# j7aen_main_ctrl_mmr0_CFG0 register map
Vendor: Texas Instruments
Peripheral module from a debugger description file (folder J722S).
Registers are 32-bit, read-write, reset 0x0 unless marked. A register's access mark holds for its fields unless they carry their own. Offsets are as the file gives them; lines under a group give offsets from that group; [hi:lo] are bit positions; {n}, {i} and the like mark numbered series; 'fields as' and 'values as' point back to an identical list; <NAME> marks a mode.

## j7aen_main_ctrl_mmr0_CFG0 (part 1 of 2)
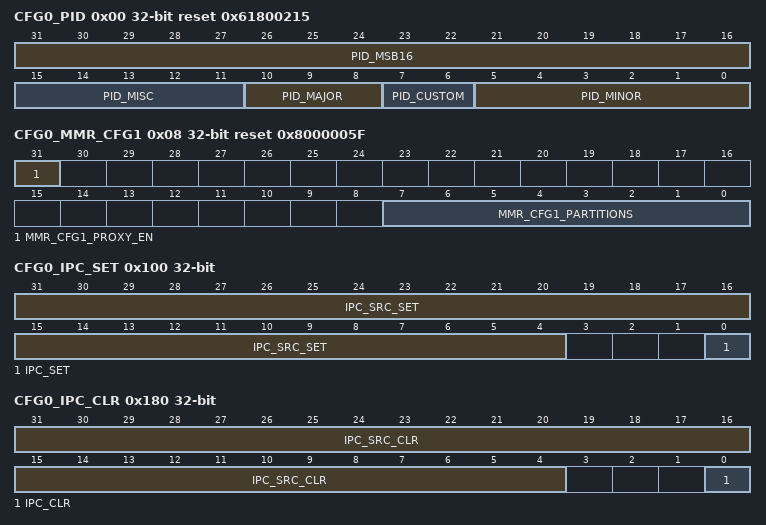
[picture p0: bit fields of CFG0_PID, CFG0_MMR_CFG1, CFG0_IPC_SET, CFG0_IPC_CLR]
0x00 CFG0_PID ro reset 0x61800215
  [31:16] PID_MSB16, [15:11] PID_MISC, [10:8] PID_MAJOR, [7:6] PID_CUSTOM, [5:0] PID_MINOR
0x08 CFG0_MMR_CFG1 ro reset 0x8000005F
  [31] MMR_CFG1_PROXY_EN — Proxy addressing activated
  [7:0] MMR_CFG1_PARTITIONS — Indicates present partitions
0x100 CFG0_IPC_SET access not given
  [31:4] IPC_SRC_SET — Read returns current value Write: 0 - No effect 1 - Sets both corresponding IPC_CLR and the IPC_SET bits (access R/W1TS)
  [0] IPC_SET — Read returns 0 Write: 0 - No effect 1 - Sets both corresponding IPC_CLR and the IPC_SET bits (access R/W1TS)
0x180 CFG0_IPC_CLR access not given
  [31:4] IPC_SRC_CLR — Read returns current value Write: 0 - No effect 1 - Clears both corresponding IPC_CLR and the IPC_SET bits (access R/W1TC)
  [0] IPC_CLR — Read returns current value Write: 0 - No effect 1 - Clears both corresponding IPC_CLR and the IPC_SET bits (access R/W1TC)
{0x1008+0x4000*i} CFG0_LOCK{i}_KICK0 (i=0..4)
  [31:0] LOCK{i}_KICK0 — - KICK0 component
{0x100C+0x4000*i} CFG0_LOCK{i}_KICK1 (i=0..4)
  [31:0] LOCK{i}_KICK1 — - KICK1 component
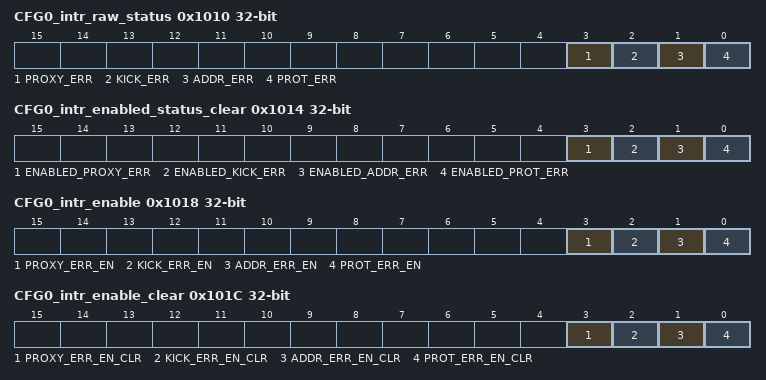
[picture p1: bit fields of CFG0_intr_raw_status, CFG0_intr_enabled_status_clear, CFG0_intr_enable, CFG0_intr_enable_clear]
0x1010 CFG0_intr_raw_status access not given
  [3] PROXY_ERR — Proxy0 access violation error. Raw status is read. Write a 1 to set the status. Writing a 0 has no effect. (access R/W1TS)
  [2] KICK_ERR — Kick access violation error. Raw status is read. Write a 1 to set the status. Writing a 0 has no effect. (access R/W1TS)
  [1] ADDR_ERR — Addressing violation error. Raw status is read. Write a 1 to set the status. Writing a 0 has no effect. (access R/W1TS)
  [0] PROT_ERR — Protection violation error. Raw status is read. Write a 1 to set the status. Writing a 0 has no effect. (access R/W1TS)
0x1014 CFG0_intr_enabled_status_clear access not given
  [3] ENABLED_PROXY_ERR — Proxy0 access violation error. Enabled status is read. Write a 1 to clear the status. Writing a 0 has no effect. (access R/W1TC)
  [2] ENABLED_KICK_ERR — Kick access violation error. Enabled status is read. Write a 1 to clear the status. Writing a 0 has no effect. (access R/W1TC)
  [1] ENABLED_ADDR_ERR — Addressing violation error. Enabled status is read. Write a 1 to clear the status. Writing a 0 has no effect. (access R/W1TC)
  [0] ENABLED_PROT_ERR — Protection violation error. Enabled status is read. Write a 1 to clear the status. Writing a 0 has no effect. (access R/W1TC)
0x1018 CFG0_intr_enable access not given
  [3] PROXY_ERR_EN — Proxy0 access violation error enable. Write a 1 to set the enable. Writing a 0 has no effect. (access R/W1TS)
  [2] KICK_ERR_EN — Kick access violation error enable. Write a 1 to set the enable. Writing a 0 has no effect. (access R/W1TS)
  [1] ADDR_ERR_EN — Addressing violation error enable. Write a 1 to set the enable. Writing a 0 has no effect. (access R/W1TS)
  [0] PROT_ERR_EN — Protection violation error enable. Write a 1 to set the enable. Writing a 0 has no effect. (access R/W1TS)
0x101C CFG0_intr_enable_clear access not given
  [3] PROXY_ERR_EN_CLR — Proxy0 access violation error enable clear. Write a 1 to clear the enable. Writing a 0 has no effect. (access R/W1TC)
  [2] KICK_ERR_EN_CLR — Kick access violation error enable clear. Write a 1 to clear the enable. Writing a 0 has no effect. (access R/W1TC)
  [1] ADDR_ERR_EN_CLR — Addressing violation error enable clear. Write a 1 to clear the enable. Writing a 0 has no effect. (access R/W1TC)
  [0] PROT_ERR_EN_CLR — Protection violation error enable clear. Write a 1 to clear the enable. Writing a 0 has no effect. (access R/W1TC)
0x1020 CFG0_eoi
  [7:0] EOI_VECTOR — EOI vector value. Write this with interrupt distribution value in the chip.
0x1024 CFG0_fault_address ro
  [31:0] FAULT_ADDR — Fault Address.
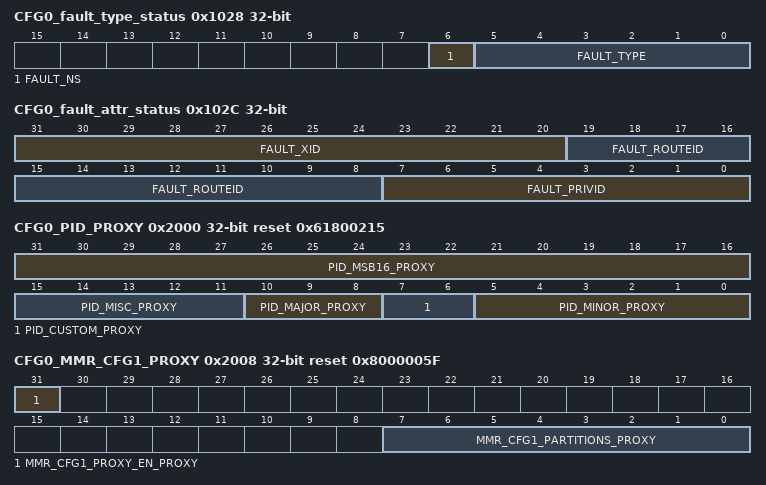
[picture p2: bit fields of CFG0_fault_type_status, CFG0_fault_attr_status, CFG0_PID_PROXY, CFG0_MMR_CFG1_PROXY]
0x1028 CFG0_fault_type_status ro
  [6] FAULT_NS — Non-secure access.
  [5:0] FAULT_TYPE — Fault Type 10_0000 = Supervisor read fault - priv = 1 dir = 1 dtype != 1 01_0000 = Supervisor write fault - priv = 1 dir = 0 00_1000 = Supervisor execute fault - priv = 1 dir = 1 dtype = 1 00_0100 = User read fault - priv = 0 dir = 1 dtype = 1 00_0010 = User write fault - priv = 0 dir = 0 00_0001 = User execute fault - priv = 0 dir = 1 dtype = 1 00_0000 = No fault
0x102C CFG0_fault_attr_status ro
  [31:20] FAULT_XID — XID.
  [19:8] FAULT_ROUTEID — Route ID.
  [7:0] FAULT_PRIVID — Privilege ID.
0x1030 CFG0_fault_clear wo
  [0] FAULT_CLR — Fault clear. Writing a 1 clears the current fault. Writing a 0 has no effect.
{0x1100+4i} CFG0_CLAIMREG_P0_R{i}_READONLY ro (i=0..6)
  [31:0] CLAIMREG_P0_R{i}_READONLY — Claim bits for Partition 0
0x2000 CFG0_PID_PROXY ro reset 0x61800215
  [31:16] PID_MSB16_PROXY, [15:11] PID_MISC_PROXY, [10:8] PID_MAJOR_PROXY, [7:6] PID_CUSTOM_PROXY, [5:0] PID_MINOR_PROXY
0x2008 CFG0_MMR_CFG1_PROXY ro reset 0x8000005F
  [31] MMR_CFG1_PROXY_EN_PROXY — Proxy addressing activated
  [7:0] MMR_CFG1_PARTITIONS_PROXY — Indicates present partitions
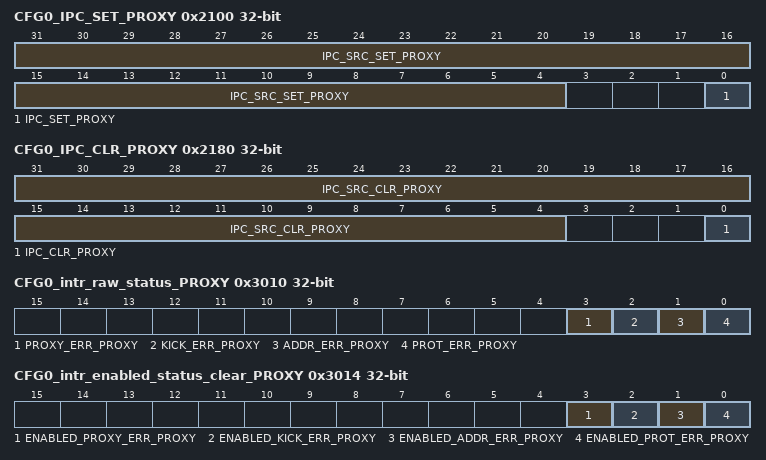
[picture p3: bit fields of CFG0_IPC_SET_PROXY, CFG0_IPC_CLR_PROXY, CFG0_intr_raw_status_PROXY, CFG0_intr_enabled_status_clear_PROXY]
0x2100 CFG0_IPC_SET_PROXY access not given
  [31:4] IPC_SRC_SET_PROXY — Read returns current value Write: 0 - No effect 1 - Sets both corresponding IPC_CLR and the IPC_SET bits (access R/W1TS)
  [0] IPC_SET_PROXY — Read returns 0 Write: 0 - No effect 1 - Sets both corresponding IPC_CLR and the IPC_SET bits (access R/W1TS)
0x2180 CFG0_IPC_CLR_PROXY access not given
  [31:4] IPC_SRC_CLR_PROXY — Read returns current value Write: 0 - No effect 1 - Clears both corresponding IPC_CLR and the IPC_SET bits (access R/W1TC)
  [0] IPC_CLR_PROXY — Read returns current value Write: 0 - No effect 1 - Clears both corresponding IPC_CLR and the IPC_SET bits (access R/W1TC)
{0x3008+0x4000*i} CFG0_LOCK{i}_KICK0_PROXY (i=0..4)
  [31:0] LOCK{i}_KICK0_PROXY — - KICK0 component
{0x300C+0x4000*i} CFG0_LOCK{i}_KICK1_PROXY (i=0..4)
  [31:0] LOCK{i}_KICK1_PROXY — - KICK1 component
0x3010 CFG0_intr_raw_status_PROXY access not given
  [3] PROXY_ERR_PROXY — Proxy0 access violation error. Raw status is read. Write a 1 to set the status. Writing a 0 has no effect. (access R/W1TS)
  [2] KICK_ERR_PROXY — Kick access violation error. Raw status is read. Write a 1 to set the status. Writing a 0 has no effect. (access R/W1TS)
  [1] ADDR_ERR_PROXY — Addressing violation error. Raw status is read. Write a 1 to set the status. Writing a 0 has no effect. (access R/W1TS)
  [0] PROT_ERR_PROXY — Protection violation error. Raw status is read. Write a 1 to set the status. Writing a 0 has no effect. (access R/W1TS)
0x3014 CFG0_intr_enabled_status_clear_PROXY access not given
  [3] ENABLED_PROXY_ERR_PROXY — Proxy0 access violation error. Enabled status is read. Write a 1 to clear the status. Writing a 0 has no effect. (access R/W1TC)
  [2] ENABLED_KICK_ERR_PROXY — Kick access violation error. Enabled status is read. Write a 1 to clear the status. Writing a 0 has no effect. (access R/W1TC)
  [1] ENABLED_ADDR_ERR_PROXY — Addressing violation error. Enabled status is read. Write a 1 to clear the status. Writing a 0 has no effect. (access R/W1TC)
  [0] ENABLED_PROT_ERR_PROXY — Protection violation error. Enabled status is read. Write a 1 to clear the status. Writing a 0 has no effect. (access R/W1TC)
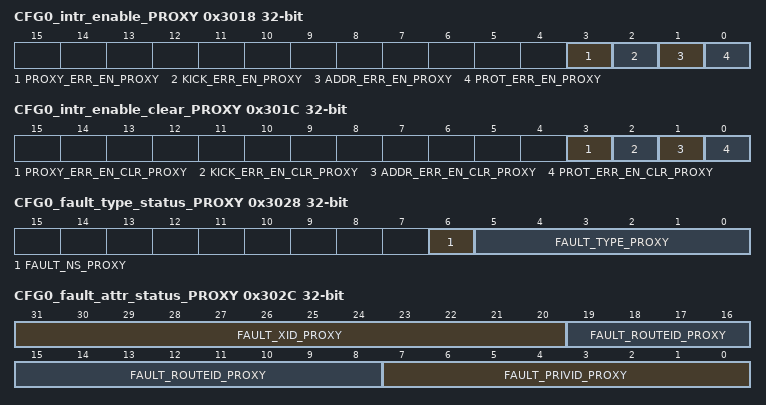
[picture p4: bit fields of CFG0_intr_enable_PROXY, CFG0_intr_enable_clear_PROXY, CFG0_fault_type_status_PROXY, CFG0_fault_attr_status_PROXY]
0x3018 CFG0_intr_enable_PROXY access not given
  [3] PROXY_ERR_EN_PROXY — Proxy0 access violation error enable. Write a 1 to set the enable. Writing a 0 has no effect. (access R/W1TS)
  [2] KICK_ERR_EN_PROXY — Kick access violation error enable. Write a 1 to set the enable. Writing a 0 has no effect. (access R/W1TS)
  [1] ADDR_ERR_EN_PROXY — Addressing violation error enable. Write a 1 to set the enable. Writing a 0 has no effect. (access R/W1TS)
  [0] PROT_ERR_EN_PROXY — Protection violation error enable. Write a 1 to set the enable. Writing a 0 has no effect. (access R/W1TS)
0x301C CFG0_intr_enable_clear_PROXY access not given
  [3] PROXY_ERR_EN_CLR_PROXY — Proxy0 access violation error enable clear. Write a 1 to clear the enable. Writing a 0 has no effect. (access R/W1TC)
  [2] KICK_ERR_EN_CLR_PROXY — Kick access violation error enable clear. Write a 1 to clear the enable. Writing a 0 has no effect. (access R/W1TC)
  [1] ADDR_ERR_EN_CLR_PROXY — Addressing violation error enable clear. Write a 1 to clear the enable. Writing a 0 has no effect. (access R/W1TC)
  [0] PROT_ERR_EN_CLR_PROXY — Protection violation error enable clear. Write a 1 to clear the enable. Writing a 0 has no effect. (access R/W1TC)
0x3020 CFG0_eoi_PROXY
  [7:0] EOI_VECTOR_PROXY — EOI vector value. Write this with interrupt distribution value in the chip.
0x3024 CFG0_fault_address_PROXY ro
  [31:0] FAULT_ADDR_PROXY — Fault Address.
0x3028 CFG0_fault_type_status_PROXY ro
  [6] FAULT_NS_PROXY — Non-secure access.
  [5:0] FAULT_TYPE_PROXY — Fault Type 10_0000 = Supervisor read fault - priv = 1 dir = 1 dtype != 1 01_0000 = Supervisor write fault - priv = 1 dir = 0 00_1000 = Supervisor execute fault - priv = 1 dir = 1 dtype = 1 00_0100 = User read fault - priv = 0 dir = 1 dtype = 1 00_0010 = User write fault - priv = 0 dir = 0 00_0001 = User execute fault - priv = 0 dir = 1 dtype = 1 00_0000 = No fault
0x302C CFG0_fault_attr_status_PROXY ro
  [31:20] FAULT_XID_PROXY — XID.
  [19:8] FAULT_ROUTEID_PROXY — Route ID.
  [7:0] FAULT_PRIVID_PROXY — Privilege ID.
0x3030 CFG0_fault_clear_PROXY wo
  [0] FAULT_CLR_PROXY — Fault clear. Writing a 1 clears the current fault. Writing a 0 has no effect.
{0x3100+4i} CFG0_CLAIMREG_P0_R{i} (i=0..6)
  [31:0] CLAIMREG_P0_R{i} — Claim bits for Partition 0
0x4044 CFG0_ENET1_CTRL reset 0x2
  [2:0] ENET1_CTRL_PORT_MODE_SEL — Selects Ethernet switch Port1 interface Field values (others are reserved): 3'b000 - GMII/MII (not supported) 3'b001 - RMII 3'b010 - RGMII 3'b011 - SGMII 3'b100 - QSGMII (not supported) 3'b101 - XFI (not supported) 3'b110 - QSGMII_SUB (not supported) 3'b111 - Reserved
0x4048 CFG0_ENET2_CTRL reset 0x2
  [2:0] ENET2_CTRL_PORT_MODE_SEL — Selects Ethernet switch Port2 interface Field values (others are reserved): 3'b000 - GMII/MII (not supported) 3'b001 - RMII 3'b010 - RGMII 3'b011 - SGMII 3'b100 - QSGMII (not supported) 3'b101 - XFI (not supported) 3'b110 - QSGMII_SUB (not supported) 3'b111 - Reserved
0x4080 CFG0_SERDES0_LN0_CTRL
  [1:0] SERDES0_LN0_CTRL_LANE_FUNC_SEL — Selects the SERDES0 lane0 function Field values (others are reserved): 2'b00 - USBSS0 2'b01 - CPSW0_SGMII2
0x4090 CFG0_SERDES1_LN0_CTRL
  [1:0] SERDES1_LN0_CTRL_LANE_FUNC_SEL — Selects the SERDES1 lane0 function Field values (others are reserved): undefined - undefined undefined - undefined undefined - undefined undefined - undefined 2'b00 - PCIE0 2'b01 - CPSW0_SGMII1
0x40E0 CFG0_SERDES0_CTRL
  [8] SERDES0_CTRL_RET_EN — Retention activate Field values (others are reserved): 1'b0 - DEACTIVATE 1'b1 - ACTIVATE
0x40E4 CFG0_SERDES1_CTRL
  [8] SERDES1_CTRL_RET_EN — Retention activate Field values (others are reserved): 1'b0 - DEACTIVATE 1'b1 - ACTIVATE
0x4128 CFG0_DPI0_OUT_SEL reset 0x1
  [1:0] DPI0_OUT_SEL_OUTSEL — Selects Source of DPI0 output Field values (others are reserved): undefined - undefined 2'b01 - DSS0_DISPC0_DPI1 2'b10 - DSS1_DISPC0_DPI0 2'b11 - DSS1_DISPC0_DPI1
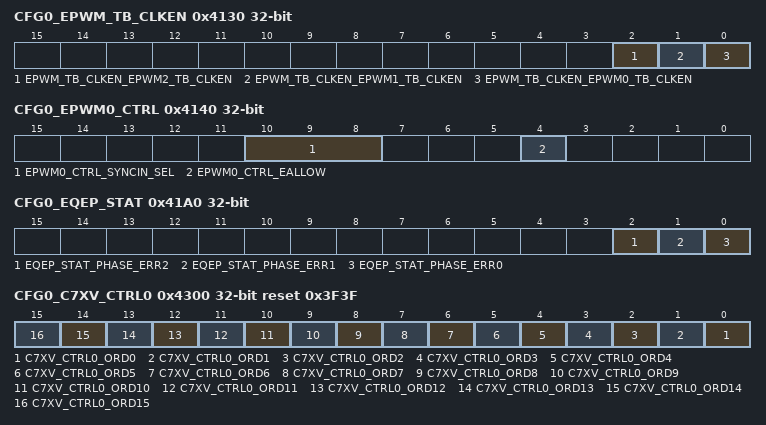
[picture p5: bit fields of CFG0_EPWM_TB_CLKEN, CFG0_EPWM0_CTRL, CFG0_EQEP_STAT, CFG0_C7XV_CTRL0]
0x4130 CFG0_EPWM_TB_CLKEN
  [2] EPWM_TB_CLKEN_EPWM2_TB_CLKEN — Activates Timebase Clock of EPWM2 When Set Field values (others are reserved): 1'b0 - DEACTIVATE 1'b1 - ACTIVATE
  [1] EPWM_TB_CLKEN_EPWM1_TB_CLKEN — Activates Timebase Clock of EPWM1 When Set Field values (others are reserved): 1'b0 - DEACTIVATE 1'b1 - ACTIVATE
  [0] EPWM_TB_CLKEN_EPWM0_TB_CLKEN — Activates Timebase Clock of EPWM0 When Set Field values (others are reserved): 1'b0 - DEACTIVATE 1'b1 - ACTIVATE
0x4140 CFG0_EPWM0_CTRL
  [10:8] EPWM0_CTRL_SYNCIN_SEL — Selects the source of the EPWM0 synchronization input Field values (others are reserved): 3'b000 - EPWM0_SYNCIN (Pin) undefined - undefined 3'b010 - Time Sync Router 19 3'b011 - CPSW CMP Event 3'b100 - PCI CMP Event
  [4] EPWM0_CTRL_EALLOW — Activate write access to EPWM tripzone registers Field values (others are reserved): 1'b0 - DEACTIVATE 1'b1 - ACTIVATE
0x4144 CFG0_EPWM1_CTRL
  [4] EPWM1_CTRL_EALLOW — Activate write access to EPWM tripzone registers Field values (others are reserved): 1'b0 - DEACTIVATE 1'b1 - ACTIVATE
0x4148 CFG0_EPWM2_CTRL
  [4] EPWM2_CTRL_EALLOW — Activate write access to EPWM tripzone registers Field values (others are reserved): 1'b0 - DEACTIVATE 1'b1 - ACTIVATE
{0x4180+4i} CFG0_EQEP{i}_CTRL (i=0..2)
  [4:0] EQEP{i}_CTRL_SOCA_SEL — Selects the source of SOCA input for EQEP{i} Field values (others are reserved): undefined - undefined undefined - undefined 5'b00010 - EPWM SOCA_OUT 5'b00011 - EPWM SOCB_OUT 5'b00100 - MCU_TIMER0 PWM 5'b00101 - MCU_TIMER1 PWM 5'b00110 - MCU_TIMER2 PWM 5'b00111 - MCU_TIMER3 PWM 5'b01000 - TIMER0 PWM 5'b01001 - TIMER1 PWM 5'b01010 - TIMER2 PWM 5'b01011 - TIMER3 PWM 5'b01100 - TIMER4 PWM 5'b01101 - TIMER5 PWM 5'b01110 - TIMER6 PWM 5'b01111 - TIMER7 PWM 5'b10000 - WKUP TIMER0 PWM undefined - undefined 5'b10001 - WKUP TIMER1 PWM
0x41A0 CFG0_EQEP_STAT ro
  [2] EQEP_STAT_PHASE_ERR2 — EQEP2 Phase error status Field values (others are reserved): 1'b0 - NO_ERROR 1'b1 - PHASE_ERROR
  [1] EQEP_STAT_PHASE_ERR1 — EQEP1 Phase error status Field values (others are reserved): 1'b0 - NO_ERROR 1'b1 - PHASE_ERROR
  [0] EQEP_STAT_PHASE_ERR0 — EQEP0 Phase error status Field values (others are reserved): 1'b0 - NO_ERROR 1'b1 - PHASE_ERROR
0x4204 CFG0_TIMER1_CTRL
  [8] TIMER1_CTRL_CASCADE_EN — Activates cascading of TIMER1 to TIMER0 Field values (others are reserved): 1'b0 - CASCADE_DEACTIVATED 1'b1 - CASCADE_ACTIVATED
0x420C CFG0_TIMER3_CTRL
  [8] TIMER3_CTRL_CASCADE_EN — Activates cascading of TIMER3 to TIMER2 Field values (others are reserved): 1'b0 - CASCADE_DEACTIVATED 1'b1 - CASCADE_ACTIVATED
0x4214 CFG0_TIMER5_CTRL
  [8] TIMER5_CTRL_CASCADE_EN — Activates cascading of TIMER5 to TIMER4 Field values (others are reserved): 1'b0 - CASCADE_DEACTIVATED 1'b1 - CASCADE_ACTIVATED
0x421C CFG0_TIMER7_CTRL
  [8] TIMER7_CTRL_CASCADE_EN — Activates cascading of TIMER7 to TIMER6 Field values (others are reserved): 1'b0 - CASCADE_DEACTIVATED 1'b1 - CASCADE_ACTIVATED
0x4300 CFG0_C7XV_CTRL0 reset 0x3F3F
  [n] C7XV_CTRL0_ORD{n} (n=0..15) — Ordering Rule for Order ID {n} Field values (others are reserved): 1'b0 - RELAXED_READ 1'b1 - RELAXED_R_TO_W
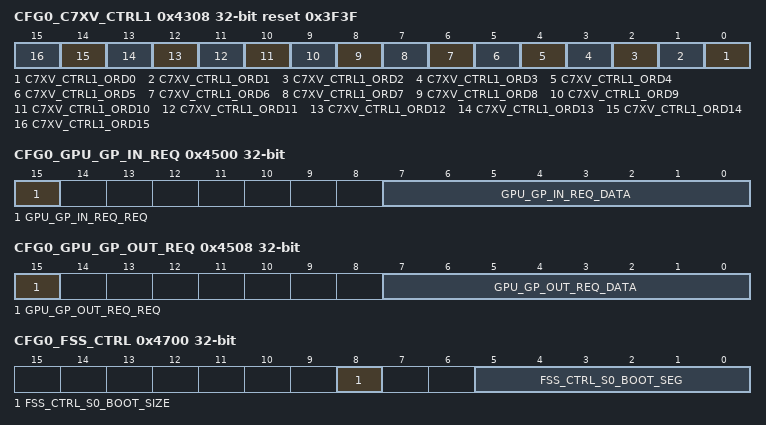
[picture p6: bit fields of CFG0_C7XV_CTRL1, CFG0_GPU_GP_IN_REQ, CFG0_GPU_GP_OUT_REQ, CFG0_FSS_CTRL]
0x4308 CFG0_C7XV_CTRL1 reset 0x3F3F
  [n] C7XV_CTRL1_ORD{n} (n=0..15) — Ordering Rule for Order ID {n} Field values (others are reserved): 1'b0 - RELAXED_READ 1'b1 - RELAXED_R_TO_W
0x4310 CFG0_DPHY_TX0_CTRL
  [1:0] DPHY_TX0_CTRL_LANE_FUNC_SEL — Selects the source for the 4 lanes of DPHY_TX 0 Field values (others are reserved): 2'b00 - DSI0 PPI0 2'b01 - CSI-TX0 2'b10 - Reserved 2'b11 - Reserved
0x4320 CFG0_VPAC_CAL0_CTRL
  [1:0] VPAC_CAL0_CTRL_CAL0_SEL — Selects the CSI-RX source for the VPAC CAL0 input Field values (others are reserved): 2'b00 - CSI_RX0 2'b01 - CSI_RX1 2'b10 - CSI_RX2 2'b11 - CSI_RX3
0x43F0 CFG0_CSI_RX_LOOPBACK
  [1:0] CSI_RX_LOOPBACK_CSITX0_LB_SEL — Selects the CSI-RX loopback source for CSI-TX0 . Field values (others are reserved): 2'b00 - CSI_RX0 2'b01 - CSI_RX1 2'b10 - CSI_RX2 2'b11 - CSI_RX3
0x44C4 CFG0_EMMC1_STAT ro
  [0] EMMC1_STAT_SIG1P8_EN — Status of 1.8V Signal Activate from EMMC1 Module Field values (others are reserved): 1'b0 - DISABLE_1P8V_SIGNALLING 1'b1 - ENABLE_1P8V_SIGNALLING
0x44C8 CFG0_EMMC2_STAT ro
  [0] EMMC2_STAT_SIG1P8_EN — Status of 1.8V Signal Activate from EMMC2 Module Field values (others are reserved): 1'b0 - DISABLE_1P8V_SIGNALLING 1'b1 - ENABLE_1P8V_SIGNALLING
0x4500 CFG0_GPU_GP_IN_REQ
  [15] GPU_GP_IN_REQ_REQ — Input request. This bit is set to generate a GPIO request to the GPU to read the requestor data input. This bit should be cleared by the requestor after the GPU has acknowledged the request. Field values (others are reserved): 1'b0 - REQ_CLR 1'b1 - REQ_SET
  [7:0] GPU_GP_IN_REQ_DATA — GPIO requestor data input to the GPU
0x4504 CFG0_GPU_GP_IN_ACK ro
  [15] GPU_GP_IN_ACK_ACK — Input acknowledge. The GPU will set this bit to acknowledge a GPIO input request. This will generate a gpu_gpio_ack interrupt which will be cleared when the requestor clears the req bit in the GPU_GP_IN_REQ register. Field values (others are reserved): 1'b0 - ACK_CLR 1'b1 - ACK_SET
0x4508 CFG0_GPU_GP_OUT_REQ ro
  [15] GPU_GP_OUT_REQ_REQ — Output request. This bit is set to generate a GPIO request from the GPU to read the requestor data output. This will generat a gpu_gpio_req interrupt which will be cleared when the receiver clears the ack bit in the GPU_GPIO_OUT_ACK register. This bit will be cleared by the GPU after the request has been acknowledged. Field values (others are reserved): 1'b0 - REQ_CLR 1'b1 - REQ_SET
  [7:0] GPU_GP_OUT_REQ_DATA — GPIO requestor data output from the GPU
0x450C CFG0_GPU_GP_OUT_ACK
  [15] GPU_GP_OUT_ACK_ACK — Output acknowledge. The receiver of the gpu_gpio_req interrupt will set this bit to acknowledge the GPIO output request. This bit is cleared when the GPU deasserts its gpio_output_req signal. Field values (others are reserved): 1'b0 - ACK_CLR 1'b1 - ACK_SET
0x4700 CFG0_FSS_CTRL
  [8] FSS_CTRL_S0_BOOT_SIZE — Selects the size of the boot block to be used for the S0 (OSPI0) flash interface Field values (others are reserved): 1'b0 - S0_BOOT_SIZE_64MB 1'b1 - S0_BOOT_SIZE_128MB
  [5:0] FSS_CTRL_S0_BOOT_SEG — Selects the boot block to be used for the S0 (OSPI0) flash interface. If the s0_boot_size is 128 MB then only bits [4:0] of this field are used. Care must be taken to account for the address translation as to not fall off or wrap the address of the flash. (e.g. if both ECC and authentication are activated for 64 MB boot, the highest valid block number is is 49, as sector 50 is only .2M Bytes in size.) Field values (others are reserved): 6'h00 - BLOCK_0 6'h01 - BLOCK_1 6'h02 - BLOCK_2 6'h03 - BLOCK_3 6'h04 - BLOCK_4 6'h05 - BLOCK_5 6'h06 - BLOCK_6 6'h07 - BLOCK_7 6'h08 - BLOCK_8 6'h09 - BLOCK_9 6'h0A - BLOCK_10 6'h0B - BLOCK_11 6'h0C - BLOCK_12 6'h0D - BLOCK_13 6'h0E - BLOCK_14 6'h0F - BLOCK_15 6'h10 - BLOCK_16 6'h11 - BLOCK_17 6'h12 - BLOCK_18 6'h13 - BLOCK_19 6'h14 - BLOCK_20 6'h15 - BLOCK_21 6'h16 - BLOCK_22 6'h17 - BLOCK_23 6'h18 - BLOCK_24 6'h19 - BLOCK_25 6'h1A - BLOCK_26 6'h1B - BLOCK_27 6'h1C - BLOCK_28 6'h1D - BLOCK_29 6'h1E - BLOCK_30 6'h1F - BLOCK_31 6'h20 - BLOCK_32 6'h21 - BLOCK_33 6'h22 - BLOCK_34 6'h23 - BLOCK_35 6'h24 - BLOCK_36 6'h25 - BLOCK_37 6'h26 - BLOCK_38 6'h27 - BLOCK_39 6'h28 - BLOCK_40 6'h29 - BLOCK_41 6'h2A - BLOCK_42 6'h2B - BLOCK_43 6'h2C - BLOCK_44 6'h2D - BLOCK_45 6'h2E - BLOCK_46 6'h2F - BLOCK_47 6'h30 - BLOCK_48 6'h31 - BLOCK_49 6'h32 - BLOCK_50 6'h33 - BLOCK_51 6'h34 - BLOCK_52 6'h35 - BLOCK_53 6'h36 - BLOCK_54 6'h37 - BLOCK_55 6'h38 - BLOCK_56 6'h39 - BLOCK_57 6'h3A - BLOCK_58 6'h3B - BLOCK_59 6'h3C - BLOCK_60 6'h3D - BLOCK_61 6'h3E - BLOCK_62 6'h3F - BLOCK_63
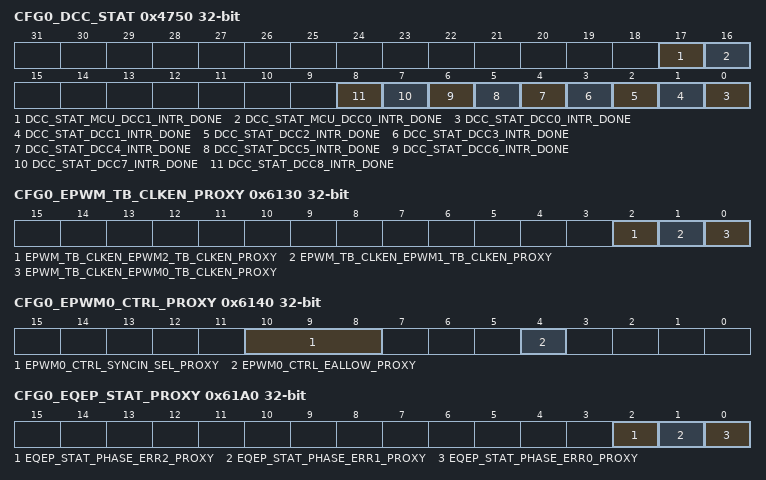
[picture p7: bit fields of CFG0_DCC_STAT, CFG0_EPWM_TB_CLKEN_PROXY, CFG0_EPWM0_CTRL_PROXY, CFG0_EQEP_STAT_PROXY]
0x4750 CFG0_DCC_STAT ro
  [17] DCC_STAT_MCU_DCC1_INTR_DONE — MCU_DCC1 Done Interrupt Status Field values (others are reserved): 1'b0 - CLR 1'b1 - PEND
  [16] DCC_STAT_MCU_DCC0_INTR_DONE — MCU_DCC0 Done Interrupt Status Field values (others are reserved): 1'b0 - CLR 1'b1 - PEND
  [n] DCC_STAT_DCC{n}_INTR_DONE (n=0..8) — DCC{n} Done Interrupt Status Field values (others are reserved): 1'b0 - CLR 1'b1 - PEND
{0x5100+4i} CFG0_CLAIMREG_P1_R{i}_READONLY ro (i=0..14)
  [31:0] CLAIMREG_P1_R{i}_READONLY — Claim bits for Partition 1
0x6044 CFG0_ENET1_CTRL_PROXY reset 0x2
  [2:0] ENET1_CTRL_PORT_MODE_SEL_PROXY — Selects Ethernet switch Port1 interface Field values (others are reserved): 3'b000 - GMII/MII (not supported) 3'b001 - RMII 3'b010 - RGMII 3'b011 - SGMII 3'b100 - QSGMII (not supported) 3'b101 - XFI (not supported) 3'b110 - QSGMII_SUB (not supported) 3'b111 - Reserved
0x6048 CFG0_ENET2_CTRL_PROXY reset 0x2
  [2:0] ENET2_CTRL_PORT_MODE_SEL_PROXY — Selects Ethernet switch Port2 interface Field values (others are reserved): 3'b000 - GMII/MII (not supported) 3'b001 - RMII 3'b010 - RGMII 3'b011 - SGMII 3'b100 - QSGMII (not supported) 3'b101 - XFI (not supported) 3'b110 - QSGMII_SUB (not supported) 3'b111 - Reserved
0x6080 CFG0_SERDES0_LN0_CTRL_PROXY
  [1:0] SERDES0_LN0_CTRL_LANE_FUNC_SEL_PROXY — Selects the SERDES0 lane0 function Field values (others are reserved): 2'b00 - USBSS0 2'b01 - CPSW0_SGMII2
0x6090 CFG0_SERDES1_LN0_CTRL_PROXY
  [1:0] SERDES1_LN0_CTRL_LANE_FUNC_SEL_PROXY — Selects the SERDES1 lane0 function Field values (others are reserved): undefined - undefined undefined - undefined undefined - undefined undefined - undefined 2'b00 - PCIE0 2'b01 - CPSW0_SGMII1
0x60E0 CFG0_SERDES0_CTRL_PROXY
  [8] SERDES0_CTRL_RET_EN_PROXY — Retention activate Field values (others are reserved): 1'b0 - DEACTIVATE 1'b1 - ACTIVATE
0x60E4 CFG0_SERDES1_CTRL_PROXY
  [8] SERDES1_CTRL_RET_EN_PROXY — Retention activate Field values (others are reserved): 1'b0 - DEACTIVATE 1'b1 - ACTIVATE
0x6128 CFG0_DPI0_OUT_SEL_PROXY reset 0x1
  [1:0] DPI0_OUT_SEL_OUTSEL_PROXY — Selects Source of DPI0 output Field values (others are reserved): undefined - undefined 2'b01 - DSS0_DISPC0_DPI1 2'b10 - DSS1_DISPC0_DPI0 2'b11 - DSS1_DISPC0_DPI1
0x6130 CFG0_EPWM_TB_CLKEN_PROXY
  [2] EPWM_TB_CLKEN_EPWM2_TB_CLKEN_PROXY — Activates Timebase Clock of EPWM2 When Set Field values (others are reserved): 1'b0 - DEACTIVATE 1'b1 - ACTIVATE
  [1] EPWM_TB_CLKEN_EPWM1_TB_CLKEN_PROXY — Activates Timebase Clock of EPWM1 When Set Field values (others are reserved): 1'b0 - DEACTIVATE 1'b1 - ACTIVATE
  [0] EPWM_TB_CLKEN_EPWM0_TB_CLKEN_PROXY — Activates Timebase Clock of EPWM0 When Set Field values (others are reserved): 1'b0 - DEACTIVATE 1'b1 - ACTIVATE
0x6140 CFG0_EPWM0_CTRL_PROXY
  [10:8] EPWM0_CTRL_SYNCIN_SEL_PROXY — Selects the source of the EPWM0 synchronization input Field values (others are reserved): 3'b000 - EPWM0_SYNCIN (Pin) undefined - undefined 3'b010 - Time Sync Router 19 3'b011 - CPSW CMP Event 3'b100 - PCI CMP Event
  [4] EPWM0_CTRL_EALLOW_PROXY — Activate write access to EPWM tripzone registers Field values (others are reserved): 1'b0 - DEACTIVATE 1'b1 - ACTIVATE
0x6144 CFG0_EPWM1_CTRL_PROXY
  [4] EPWM1_CTRL_EALLOW_PROXY — Activate write access to EPWM tripzone registers Field values (others are reserved): 1'b0 - DEACTIVATE 1'b1 - ACTIVATE
0x6148 CFG0_EPWM2_CTRL_PROXY
  [4] EPWM2_CTRL_EALLOW_PROXY — Activate write access to EPWM tripzone registers Field values (others are reserved): 1'b0 - DEACTIVATE 1'b1 - ACTIVATE
{0x6180+4i} CFG0_EQEP{i}_CTRL_PROXY (i=0..2)
  [4:0] EQEP{i}_CTRL_SOCA_SEL_PROXY — Selects the source of SOCA input for EQEP{i} Field values (others are reserved): undefined - undefined undefined - undefined 5'b00010 - EPWM SOCA_OUT 5'b00011 - EPWM SOCB_OUT 5'b00100 - MCU_TIMER0 PWM 5'b00101 - MCU_TIMER1 PWM 5'b00110 - MCU_TIMER2 PWM 5'b00111 - MCU_TIMER3 PWM 5'b01000 - TIMER0 PWM 5'b01001 - TIMER1 PWM 5'b01010 - TIMER2 PWM 5'b01011 - TIMER3 PWM 5'b01100 - TIMER4 PWM 5'b01101 - TIMER5 PWM 5'b01110 - TIMER6 PWM 5'b01111 - TIMER7 PWM 5'b10000 - WKUP TIMER0 PWM undefined - undefined 5'b10001 - WKUP TIMER1 PWM
0x61A0 CFG0_EQEP_STAT_PROXY ro
  [2] EQEP_STAT_PHASE_ERR2_PROXY — EQEP2 Phase error status Field values (others are reserved): 1'b0 - NO_ERROR 1'b1 - PHASE_ERROR
  [1] EQEP_STAT_PHASE_ERR1_PROXY — EQEP1 Phase error status Field values (others are reserved): 1'b0 - NO_ERROR 1'b1 - PHASE_ERROR
  [0] EQEP_STAT_PHASE_ERR0_PROXY — EQEP0 Phase error status Field values (others are reserved): 1'b0 - NO_ERROR 1'b1 - PHASE_ERROR
0x6204 CFG0_TIMER1_CTRL_PROXY
  [8] TIMER1_CTRL_CASCADE_EN_PROXY — Activates cascading of TIMER1 to TIMER0 Field values (others are reserved): 1'b0 - CASCADE_DEACTIVATED 1'b1 - CASCADE_ACTIVATED
0x620C CFG0_TIMER3_CTRL_PROXY
  [8] TIMER3_CTRL_CASCADE_EN_PROXY — Activates cascading of TIMER3 to TIMER2 Field values (others are reserved): 1'b0 - CASCADE_DEACTIVATED 1'b1 - CASCADE_ACTIVATED
0x6214 CFG0_TIMER5_CTRL_PROXY
  [8] TIMER5_CTRL_CASCADE_EN_PROXY — Activates cascading of TIMER5 to TIMER4 Field values (others are reserved): 1'b0 - CASCADE_DEACTIVATED 1'b1 - CASCADE_ACTIVATED
0x621C CFG0_TIMER7_CTRL_PROXY
  [8] TIMER7_CTRL_CASCADE_EN_PROXY — Activates cascading of TIMER7 to TIMER6 Field values (others are reserved): 1'b0 - CASCADE_DEACTIVATED 1'b1 - CASCADE_ACTIVATED
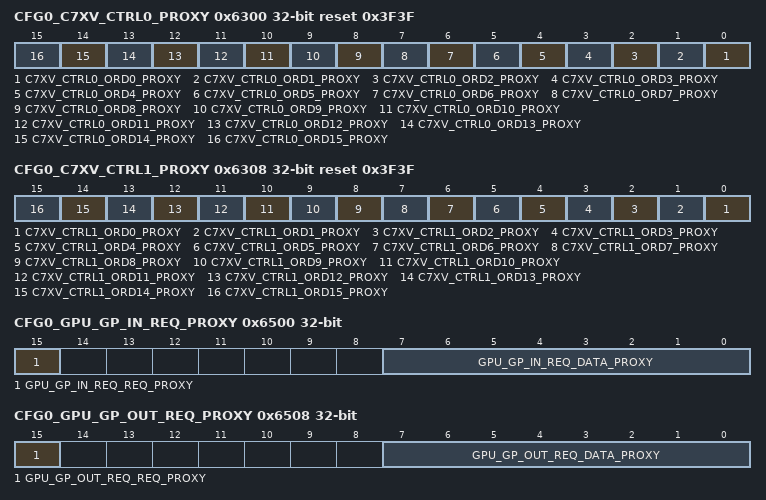
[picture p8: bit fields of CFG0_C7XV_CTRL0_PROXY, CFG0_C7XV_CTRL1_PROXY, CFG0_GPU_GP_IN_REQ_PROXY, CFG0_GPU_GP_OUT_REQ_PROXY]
0x6300 CFG0_C7XV_CTRL0_PROXY reset 0x3F3F
  [n] C7XV_CTRL0_ORD{n}_PROXY (n=0..15) — Ordering Rule for Order ID {n} Field values (others are reserved): 1'b0 - RELAXED_READ 1'b1 - RELAXED_R_TO_W
0x6308 CFG0_C7XV_CTRL1_PROXY reset 0x3F3F
  [n] C7XV_CTRL1_ORD{n}_PROXY (n=0..15) — Ordering Rule for Order ID {n} Field values (others are reserved): 1'b0 - RELAXED_READ 1'b1 - RELAXED_R_TO_W
0x6310 CFG0_DPHY_TX0_CTRL_PROXY
  [1:0] DPHY_TX0_CTRL_LANE_FUNC_SEL_PROXY — Selects the source for the 4 lanes of DPHY_TX 0 Field values (others are reserved): 2'b00 - DSI0 PPI0 2'b01 - CSI-TX0 2'b10 - Reserved 2'b11 - Reserved
0x6320 CFG0_VPAC_CAL0_CTRL_PROXY
  [1:0] VPAC_CAL0_CTRL_CAL0_SEL_PROXY — Selects the CSI-RX source for the VPAC CAL0 input Field values (others are reserved): 2'b00 - CSI_RX0 2'b01 - CSI_RX1 2'b10 - CSI_RX2 2'b11 - CSI_RX3
0x63F0 CFG0_CSI_RX_LOOPBACK_PROXY
  [1:0] CSI_RX_LOOPBACK_CSITX0_LB_SEL_PROXY — Selects the CSI-RX loopback source for CSI-TX0 . Field values (others are reserved): 2'b00 - CSI_RX0 2'b01 - CSI_RX1 2'b10 - CSI_RX2 2'b11 - CSI_RX3
0x64C4 CFG0_EMMC1_STAT_PROXY ro
  [0] EMMC1_STAT_SIG1P8_EN_PROXY — Status of 1.8V Signal Activate from EMMC1 Module Field values (others are reserved): 1'b0 - DISABLE_1P8V_SIGNALLING 1'b1 - ENABLE_1P8V_SIGNALLING
0x64C8 CFG0_EMMC2_STAT_PROXY ro
  [0] EMMC2_STAT_SIG1P8_EN_PROXY — Status of 1.8V Signal Activate from EMMC2 Module Field values (others are reserved): 1'b0 - DISABLE_1P8V_SIGNALLING 1'b1 - ENABLE_1P8V_SIGNALLING
0x6500 CFG0_GPU_GP_IN_REQ_PROXY
  [15] GPU_GP_IN_REQ_REQ_PROXY — Input request. This bit is set to generate a GPIO request to the GPU to read the requestor data input. This bit should be cleared by the requestor after the GPU has acknowledged the request. Field values (others are reserved): 1'b0 - REQ_CLR 1'b1 - REQ_SET
  [7:0] GPU_GP_IN_REQ_DATA_PROXY — GPIO requestor data input to the GPU
0x6504 CFG0_GPU_GP_IN_ACK_PROXY ro
  [15] GPU_GP_IN_ACK_ACK_PROXY — Input acknowledge. The GPU will set this bit to acknowledge a GPIO input request. This will generate a gpu_gpio_ack interrupt which will be cleared when the requestor clears the req bit in the GPU_GP_IN_REQ register. Field values (others are reserved): 1'b0 - ACK_CLR 1'b1 - ACK_SET
0x6508 CFG0_GPU_GP_OUT_REQ_PROXY ro
  [15] GPU_GP_OUT_REQ_REQ_PROXY — Output request. This bit is set to generate a GPIO request from the GPU to read the requestor data output. This will generat a gpu_gpio_req interrupt which will be cleared when the receiver clears the ack bit in the GPU_GPIO_OUT_ACK register. This bit will be cleared by the GPU after the request has been acknowledged. Field values (others are reserved): 1'b0 - REQ_CLR 1'b1 - REQ_SET
  [7:0] GPU_GP_OUT_REQ_DATA_PROXY — GPIO requestor data output from the GPU
0x650C CFG0_GPU_GP_OUT_ACK_PROXY
  [15] GPU_GP_OUT_ACK_ACK_PROXY — Output acknowledge. The receiver of the gpu_gpio_req interrupt will set this bit to acknowledge the GPIO output request. This bit is cleared when the GPU deasserts its gpio_output_req signal. Field values (others are reserved): 1'b0 - ACK_CLR 1'b1 - ACK_SET
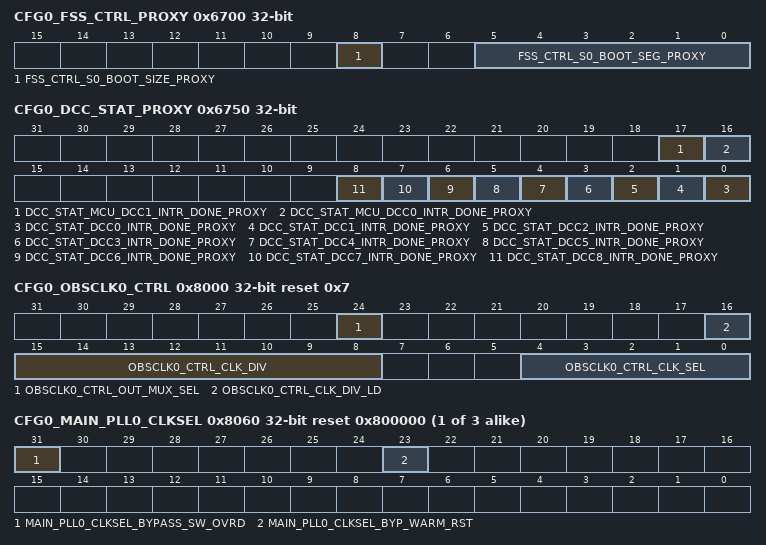
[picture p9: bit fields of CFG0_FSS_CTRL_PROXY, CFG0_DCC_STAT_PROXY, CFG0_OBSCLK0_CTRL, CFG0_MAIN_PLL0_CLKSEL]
0x6700 CFG0_FSS_CTRL_PROXY
  [8] FSS_CTRL_S0_BOOT_SIZE_PROXY — Selects the size of the boot block to be used for the S0 (OSPI0) flash interface Field values (others are reserved): 1'b0 - S0_BOOT_SIZE_64MB 1'b1 - S0_BOOT_SIZE_128MB
  [5:0] FSS_CTRL_S0_BOOT_SEG_PROXY — Selects the boot block to be used for the S0 (OSPI0) flash interface. If the s0_boot_size is 128 MB then only bits [4:0] of this field are used. Care must be taken to account for the address translation as to not fall off or wrap the address of the flash. (e.g. if both ECC and authentication are activated for 64 MB boot, the highest valid block number is is 49, as sector 50 is only .2M Bytes in size.) Field values (others are reserved): 6'h00 - BLOCK_0 6'h01 - BLOCK_1 6'h02 - BLOCK_2 6'h03 - BLOCK_3 6'h04 - BLOCK_4 6'h05 - BLOCK_5 6'h06 - BLOCK_6 6'h07 - BLOCK_7 6'h08 - BLOCK_8 6'h09 - BLOCK_9 6'h0A - BLOCK_10 6'h0B - BLOCK_11 6'h0C - BLOCK_12 6'h0D - BLOCK_13 6'h0E - BLOCK_14 6'h0F - BLOCK_15 6'h10 - BLOCK_16 6'h11 - BLOCK_17 6'h12 - BLOCK_18 6'h13 - BLOCK_19 6'h14 - BLOCK_20 6'h15 - BLOCK_21 6'h16 - BLOCK_22 6'h17 - BLOCK_23 6'h18 - BLOCK_24 6'h19 - BLOCK_25 6'h1A - BLOCK_26 6'h1B - BLOCK_27 6'h1C - BLOCK_28 6'h1D - BLOCK_29 6'h1E - BLOCK_30 6'h1F - BLOCK_31 6'h20 - BLOCK_32 6'h21 - BLOCK_33 6'h22 - BLOCK_34 6'h23 - BLOCK_35 6'h24 - BLOCK_36 6'h25 - BLOCK_37 6'h26 - BLOCK_38 6'h27 - BLOCK_39 6'h28 - BLOCK_40 6'h29 - BLOCK_41 6'h2A - BLOCK_42 6'h2B - BLOCK_43 6'h2C - BLOCK_44 6'h2D - BLOCK_45 6'h2E - BLOCK_46 6'h2F - BLOCK_47 6'h30 - BLOCK_48 6'h31 - BLOCK_49 6'h32 - BLOCK_50 6'h33 - BLOCK_51 6'h34 - BLOCK_52 6'h35 - BLOCK_53 6'h36 - BLOCK_54 6'h37 - BLOCK_55 6'h38 - BLOCK_56 6'h39 - BLOCK_57 6'h3A - BLOCK_58 6'h3B - BLOCK_59 6'h3C - BLOCK_60 6'h3D - BLOCK_61 6'h3E - BLOCK_62 6'h3F - BLOCK_63
0x6750 CFG0_DCC_STAT_PROXY ro
  [17] DCC_STAT_MCU_DCC1_INTR_DONE_PROXY — MCU_DCC1 Done Interrupt Status Field values (others are reserved): 1'b0 - CLR 1'b1 - PEND
  [16] DCC_STAT_MCU_DCC0_INTR_DONE_PROXY — MCU_DCC0 Done Interrupt Status Field values (others are reserved): 1'b0 - CLR 1'b1 - PEND
  [n] DCC_STAT_DCC{n}_INTR_DONE_PROXY (n=0..8) — DCC{n} Done Interrupt Status Field values (others are reserved): 1'b0 - CLR 1'b1 - PEND
{0x7100+4i} CFG0_CLAIMREG_P1_R{i} (i=0..14)
  [31:0] CLAIMREG_P1_R{i} — Claim bits for Partition 1
0x8000 CFG0_OBSCLK0_CTRL reset 0x7
  [24] OBSCLK0_CTRL_OUT_MUX_SEL — OBSCLK pin output mux selection. HFOSC0_CLK is a direct output from the HFOSC0 Field values (others are reserved): 1'b0 - CLK_DIV_OUT 1'b1 - HFOSC0_CLK (clk_sel must be OFF)
  [16] OBSCLK0_CTRL_CLK_DIV_LD — Load divisor value from clk_div field, when the bit is toggled from 0 to 1. Field values (others are reserved): 1'b0 - READY 1'b1 - LOAD
  [15:8] OBSCLK0_CTRL_CLK_DIV — OBSCLK0 output divider. Sets divider to divide by clkdiv + 1. Divide by 1 to 256 are supported. After writing to this field, the clk_div_ld field must be toggled.
  [4:0] OBSCLK0_CTRL_CLK_SEL — OBSCLK0 clock source selection. Selects the source of the clock to be divided by the OBSCLK0 divider. Field values (others are reserved): 5'b00000 - MAIN_PLL0_HSDIV0_CLKOUT 5'b00001 - MAIN_PLL1_HSDIV0_CLKOUT 5'b00010 - MAIN_PLL2_HSDIV0_CLKOUT 5'b00011 - MPUSS_CLK_DIV4 5'b00100 - DDRSS_CLK_DIV4 5'b00101 - CLK_12M_RC 5'b00110 - HFOSC0_CLKOUT_32K 5'b00111 - PLLCTRL_OBSCLK 5'b01000 - HFOSC0_CLKOUT 5'b01001 - CLK_32K_RC 5'b01010 - CPSW0_CPTS_GENF0 5'b01011 - CPSW0_CPTS_GENF1 5'b01100 - MCU_PLL0_HSDIV0_CLKOUT 5'b01101 - MAIN_PLL15_HSDIV0_CLKOUT 5'b01110 - MAIN_PLL16_HSDIV0_CLKOUT_DIV8 undefined - undefined 5'b01111 - MAIN_PLL17_HSDIV0_CLKOUT 5'b10000 - MAIN_SYSCLK0 5'b10001 - DEVICE_CLKOUT_32K 5'b10010 - MAIN_PLL5_HSDIV0_CLKOUT_DIV2 5'b10011 - C7XV256_CLK_DIV4 5'b10100 - MAIN_PLL6_HSDIV0_CLKOUT_DIV4 5'b10101 - MAIN_PLL18_HSDIV0_CLKOUT_DIV2 5'b11111 - OFF (Must Select this option when out_mux_sel is set to HFOSC0_CLK)
0x8010 CFG0_CLKOUT_CTRL
  [0] CLKOUT_CTRL_CLK_SEL — Selects CLKOUT clock source Field values (others are reserved): 1'b0 - MAIN_PLL2_HSDIV1_CLKOUT / 5 1'b1 - MAIN_PLL2_HSDIV1_CLKOUT / 10
{0x8060+4i} CFG0_MAIN_PLL{i}_CLKSEL reset 0x800000 (i=0..2)
  [31] MAIN_PLL{i}_CLKSEL_BYPASS_SW_OVRD — PLL Bypass warm reset software override When set, activates software control of exit from bypass mode on a main_reset_z for MAIN PLL{i}. This bit must not be set until after the corresponding byp_warm_rst bit has been cleared or the PLL will immediately enter bypass mode. Field values (others are reserved): 1'b0 - DEACTIVATE 1'b1 - ACTIVATE
  [23] MAIN_PLL{i}_CLKSEL_BYP_WARM_RST — PLL bypass mode after warm reset. This bit is only valid when bypass_sw_ovrd is set to 1'b1 to activate bypass software override. This bit is set (1'b1) when a MAIN warm reset occurs and will keep MAIN PLL{i} in bypass mode after reset exit until cleared by software. Field values (others are reserved): 1'b0 - EXIT_BYPASS 1'b1 - MAINTAIN_BYPASS
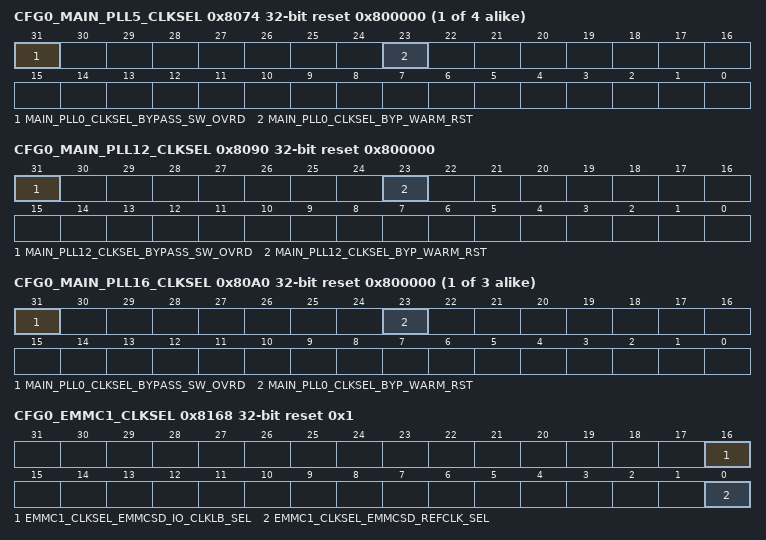
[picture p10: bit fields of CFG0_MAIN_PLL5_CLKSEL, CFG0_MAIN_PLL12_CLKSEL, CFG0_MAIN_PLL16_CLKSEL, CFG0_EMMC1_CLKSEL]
{0x8060+4i} CFG0_MAIN_PLL{i}_CLKSEL reset 0x800000 (i=5..8)
  fields as CFG0_MAIN_PLL0_CLKSEL
0x8090 CFG0_MAIN_PLL12_CLKSEL reset 0x800000
  [31] MAIN_PLL12_CLKSEL_BYPASS_SW_OVRD — PLL Bypass warm reset software override When set, activates software control of exit from bypass mode on a main_reset_z for MAIN PLL12. This bit must not be set until after the corresponding byp_warm_rst bit has been cleared or the PLL will immediately enter bypass mode. Field values (others are reserved): 1'b0 - DEACTIVATE 1'b1 - ACTIVATE
  [23] MAIN_PLL12_CLKSEL_BYP_WARM_RST — PLL bypass mode after warm reset. This bit is only valid when bypass_sw_ovrd is set to 1'b1 to activate bypass software override. This bit is set (1'b1) when a MAIN warm reset occurs and will keep MAIN PLL12 in bypass mode after reset exit until cleared by software. Field values (others are reserved): 1'b0 - EXIT_BYPASS 1'b1 - MAINTAIN_BYPASS
{0x8060+4i} CFG0_MAIN_PLL{i}_CLKSEL reset 0x800000 (i=16..18)
  fields as CFG0_MAIN_PLL0_CLKSEL
0x8120 CFG0_PCIE0_CLKSEL
  [2:0] PCIE0_CLKSEL_CPTS_CLKSEL — Selects the clock source for the PCIE0 Common Platform Time Stamp module Field values (others are reserved): 3'b000 - MAIN_PLL2_HSDIV6_CLKOUT 3'b001 - MAIN_PLL0_HSDIV6_CLKOUT 3'b010 - CP_GEMAC_CPTS0_RFT_CLK (Pin) undefined - undefined 3'b011 - Reserved 3'b100 - MCU_EXT_REFCLK0 (Pin) 3'b101 - EXT_REFCLK1 (Pin) 3'b110 - SERDES1_IP1_LN0_TXMCLK 3'b111 - Reserved
0x8140 CFG0_CPSW_CLKSEL reset 0x7
  [2:0] CPSW_CLKSEL_CPTS_CLKSEL — Selects the clock source for the CPSW Ethernet switch Common Platform Time Stamp module Field values (others are reserved): 3'b000 - MAIN_PLL2_HSDIV5_CLKOUT 3'b001 - MAIN_PLL0_HSDIV6_CLKOUT 3'b010 - CP_GEMAC_CPTS0_RFT_CLK (Pin) 3'b011 - Reserved 3'b100 - MCU_EXT_REFCLK0 (Pin) 3'b101 - EXT_REFCLK1 (Pin) 3'b110 - SERDES0_IP1_LN0_TXMCLK undefined - undefined 3'b111 - MAIN_SYSCLK0
0x8160 CFG0_EMMC0_CLKSEL
  [0] EMMC0_CLKSEL_EMMCSD_REFCLK_SEL — Selects the functional clock for the MMC Module Field values (others are reserved): 1'b0 - MAIN_PLL0_HSDIV5_CLKOUT 1'b1 - MAIN_PLL2_HSDIV2_CLKOUT
0x8168 CFG0_EMMC1_CLKSEL reset 0x1
  [16] EMMC1_CLKSEL_EMMCSD_IO_CLKLB_SEL — Selects IO Pad Loopback for the MMC Module Field values (others are reserved): 1'b0 - Loopback from Unbonded Pad MMCSD1_CLKLB 1'b1 - Loopback from IO Pin MMCSD1_CLK
  [0] EMMC1_CLKSEL_EMMCSD_REFCLK_SEL — Selects the functional clock for the MMC Module Field values (others are reserved): 1'b0 - MAIN_PLL0_HSDIV5_CLKOUT 1'b1 - MAIN_PLL2_HSDIV2_CLKOUT
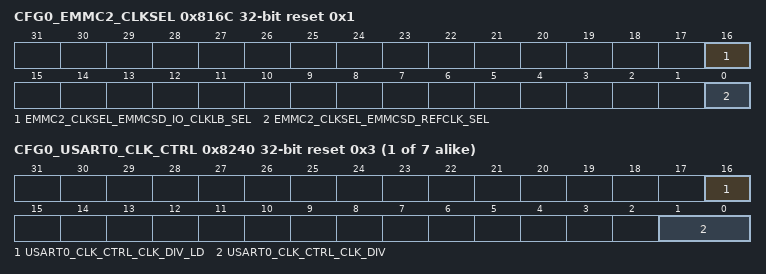
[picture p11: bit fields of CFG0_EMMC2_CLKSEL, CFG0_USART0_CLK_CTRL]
0x816C CFG0_EMMC2_CLKSEL reset 0x1
  [16] EMMC2_CLKSEL_EMMCSD_IO_CLKLB_SEL — Selects IO Pad Loopback for the MMC Module Field values (others are reserved): 1'b0 - Loopback from Unbonded Pad MMCSD2_CLKLB 1'b1 - Loopback from IO Pin MMCSD2_CLK
  [0] EMMC2_CLKSEL_EMMCSD_REFCLK_SEL — Selects the functional clock for the MMC Module Field values (others are reserved): 1'b0 - MAIN_PLL0_HSDIV5_CLKOUT 1'b1 - MAIN_PLL2_HSDIV2_CLKOUT
0x8180 CFG0_GPMC_CLKSEL
  [0] GPMC_CLKSEL_CLK_SEL — Selects the GPMC clock source: Field values (others are reserved): 1'b0 - MAIN_PLL0_HSDIV3_CLKOUT 1'b1 - MAIN_PLL2_HSDIV7_CLKOUT
{0x81B0+4i} CFG0_TIMER{i}_CLKSEL (i=0..7)
  [3:0] TIMER{i}_CLKSEL_CLK_SEL — Timer functional clock input select mux control (Reserved values default to HFOSC0_CLK) Field values (others are reserved): 4'b0000 - HFOSC0_CLKOUT 4'b0001 - DEVICE_CLKOUT_32K 4'b0010 - MAIN_PLL0_HSDIV7_CLKOUT 4'b0011 - CLK_12M_RC 4'b0100 - MCU_EXT_REFCLK0 (Pin) 4'b0101 - EXT_REFCLK1 (Pin) 4'b0110 - Reserved 4'b0111 - CP_GEMAC_CPTS0_RFT_CLK (Pin) 4'b1000 - MAIN_PLL1_HSDIV3_CLKOUT 4'b1001 - MAIN_PLL2_HSDIV6_CLKOUT 4'b1010 - CPSW0_CPTS_GENF0 4'b1011 - CPSW0_CPTS_GENF1 4'b1100 - MAIN_PLL5_HSDIV1_CLKOUT
{0x8200+4i} CFG0_SPI{i}_CLKSEL (i=0..2)
  [16] SPI{i}_CLKSEL_MSTR_LB_CLKSEL — Controller mode receive capture clock loopback selection Field values (others are reserved): 1'b0 - INTERNAL_LOOPBACK 1'b1 - EXTERNAL_LOOPBACK
{0x8240+4i} CFG0_USART{i}_CLK_CTRL reset 0x3 (i=0..6)
  [16] USART{i}_CLK_CTRL_CLK_DIV_LD — Load the output divider value Writing 1 to this bit will generate a load pulse to load the USART{i} clock programmable divider value. This bit can be cleared but must not be set in the same write cycle in which the clk_div value is changed. Field values (others are reserved): 1'b0 - READY 1'b1 - LOAD
  [1:0] USART{i}_CLK_CTRL_CLK_DIV — Selects the clock divider value. Supports divide values of 1 to 4 Default is /4. To load the new divider value the clk_div_ld bit must be cleared and then set to 1. Field values (others are reserved): 2'b00 - Divide by 1 2'b01 - Divide by 2 2'b10 - Divide by 3 2'b11 - Divide by 4
